# ATA5702M322 device description
Architecture: AVR8; Family: megaAVR
Registers are 8-bit, access not given, no defined reset value unless marked. A register's access mark holds for its fields unless they carry their own. Offsets are from the block's base; [hi:lo] are bit positions; {n}, {i} and the like mark numbered series.

## TPLF_CAL
Instances: TPLF_CAL 0x00
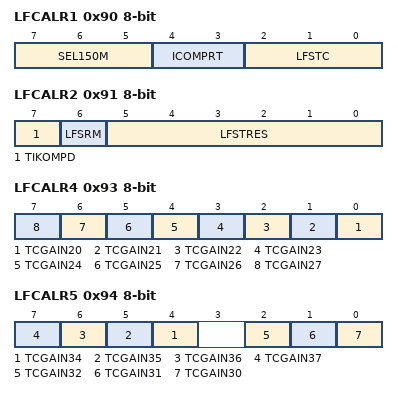
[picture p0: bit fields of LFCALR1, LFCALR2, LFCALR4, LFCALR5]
0x90 LFCALR1 — LF Receiver Calibration Register 1
  [7:5] SEL150M — Bandgap Calibration of VREF1
  [4:3] ICOMPRT — icomp_range_trim
  [2:0] LFSTC — lf_stim_trim_current
0x91 LFCALR2 — LF Receiver Calibration Register 2
  [7] TIKOMPD — trim_ikomp_data
  [6] LFSRM — lf_stim_res_mode
  [5:0] LFSTRES — lf_stim_trim_res
0x92 LFCALR3 — LF Receiver Calibration Register 3
  [7:0] TCGAIN1 — Trim coarse gain
0x93 LFCALR4 — LF Receiver Calibration Register 4
  [n-20] TCGAIN{n} (n=20..27) — Trim coarse gain bit {n-12}
0x94 LFCALR5 — LF Receiver Calibration Register 5
  [n-30] TCGAIN{n} (n=34..37) — Trim coarse gain bit {n-14}
  [2] TCGAIN32 — Trim coarse gain bit 18
  [1] TCGAIN31 — Trim coarse gain bit 17
  [0] TCGAIN30 — Trim coarse gain bit 16
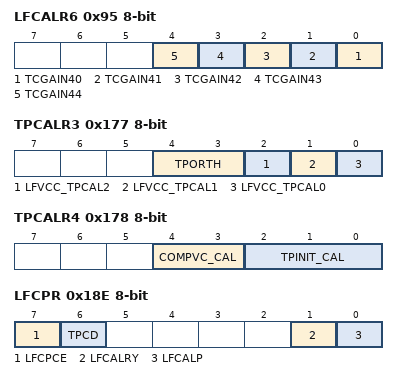
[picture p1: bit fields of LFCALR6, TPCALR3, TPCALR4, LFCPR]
0x95 LFCALR6 — LF Receiver Calibration Register 6
  [n-40] TCGAIN{n} (n=40..44) — Trim coarse gain bit {n-16}
0x96 LFCALR7 — LF Receiver Calibration Register 7
0x97 LFCALR8 bits used 4:0 — LF Receiver Calibration Register 8
0x98 LFCALR9 — LF Receiver Calibration Register 9
0x99 LFCALR10 bits used 6:0 — LF Receiver Calibration Register 10
{0x8F+i} LFCALR{i} (i=11..13) — LF Receiver Calibration Register {i}
0x9D LFCALR14 bits used 6:0 — LF Receiver Calibration Register 14
0x9E LFCALR15 — LF Receiver Calibration Register 15
0x9F LFCALR16 bits used 4:0 — LF Receiver Calibration Register 16
0xA0 LFCALR17 bits used 4:0 — LF Receiver Calibration Register 17
0xA1 LFCALR18 — LF Receiver Calibration Register 18
0xA2 LFCALR19 bits used 6:0 — LF Receiver Calibration Register 19
{0x8F+i} LFCALR{i} (i=20..22) — LF Receiver Calibration Register {i}
0xA6 LFCALR23 bits used 6:0 — LF Receiver Calibration Register 23
0xA7 LFCALR24 — LF Receiver Calibration Register 24
0xA8 LFCALR25 bits used 4:0 — LF Receiver Calibration Register 25
0xA9 LFCALR26 bits used 4:0 — LF Receiver Calibration Register 26
0xAA LFCALR27 — LF Receiver Calibration Register 27
0xAB LFCALR28 bits used 6:0 — LF Receiver Calibration Register 28
{0x8F+i} LFCALR{i} (i=29..31) — LF Receiver Calibration Register {i}
0xAF LFCALR32 bits used 6:0 — LF Receiver Calibration Register 32
0xB0 LFCALR33 — LF Receiver Calibration Register 33
0xB1 LFCALR34 bits used 4:0 — LF Receiver Calibration Register 34
0xB2 LFCALR35 — LF Receiver Calibration Register 35
0xB3 LFCALR36 bits used 6:0 — LF Receiver Calibration Register 36
0xB4 LFCALR37 bits used 5:0 — LF Receiver Calibration Register 37
{0x8F+i} LFCALR{i} bits used 3:0 (i=38..40) — LF Receiver Calibration Register {i}
{0x8F+i} LFCALR{i} (i=41..43) — LF Receiver Calibration Register {i}
0xBB LFCALR44 bits used 5:0 — LF Receiver Calibration Register 44
{0x8F+i} LFCALR{i} (i=45..47) — LF Receiver Calibration Register {i}
0xBF LFCALR48 bits used 5:0 — LF Receiver Calibration Register 48
{0x8F+i} LFCALR{i} (i=49..51) — LF Receiver Calibration Register {i}
0xC3 LFCALR52 bits used 5:0 — LF Receiver Calibration Register 52
0xC4 LFCALR53 — LF Receiver Calibration Register 53
0x175 TPCALR1 — Transponder Calibration Register 1
  [5:0] TPBG_IREF — Transponder Bandgap IREF
0x176 TPCALR2 — Transponder Calibration Register 2
  [6:0] TPBG_UREF — Transponder Bandgap UREF
0x177 TPCALR3 — Transponder Calibration Register 3
  [4:3] TPORTH — Transponder Power On Reset Threshold
  [2] LFVCC_TPCAL2 — Not used
  [1] LFVCC_TPCAL1 — Not used
  [0] LFVCC_TPCAL0 — Not used
0x178 TPCALR4 — Transponder Calibration Register 4
  [4:3] COMPVC_CAL — Comparator VC Calibration
  [2:0] TPINIT_CAL — Transponder Init Calibration
0x179 TPCALR5 bits used 3:0 — Transponder Calibration Register 5
0x17A TPCALR6 bits used 4:0 — Transponder Calibration Register 6
0x17B TPCALR7 bits used 2:0 — Transponder Calibration Register 7
0x17C TPCALR8 bits used 6:0 — Transponder Calibration Register 8
0x17D TPCALR9 — Transponder Calibration Register 9
0x17E TPCALR10 bits used 6:0 — Transponder Calibration Register 10
0x18E LFCPR — LF Receiver Calibration Protect Register
  [7] LFCPCE — LF Calibration Protect Change Enable
  [6] TPCD — Transponder Constant Disable
  [1] LFCALRY — LF Calibration Ready
  [0] LFCALP — LF Calibration Protection
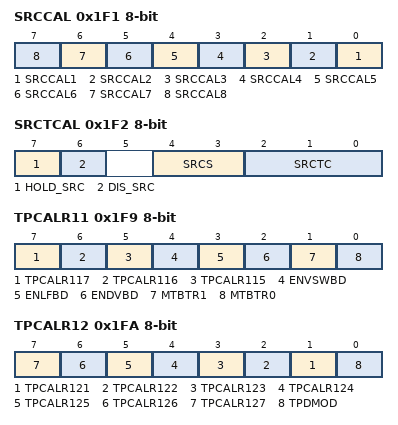
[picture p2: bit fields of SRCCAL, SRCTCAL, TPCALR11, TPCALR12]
0x1F1 SRCCAL — Slow RC oscillator calibration
  [n-1] SRCCAL{n} (n=1..8) — Slow RC oscillator calibration bit {n}
0x1F2 SRCTCAL — SRC oscillator Temperature Compensation register
  [7] HOLD_SRC — Stop SRC-Osccillator output
  [6] DIS_SRC — Disable SRC Bandgap
  [4:3] SRCS — SRC Oscillator Select delta current
  [2:0] SRCTC — SRC Oscillator Temperature Compensation
0x1F9 TPCALR11 — Transponder Calibration Register 11
  [7] TPCALR117
  [6] TPCALR116
  [5] TPCALR115
  [4] ENVSWBD — Enable VSW Brown Out Detection
  [3] ENLFBD — Enable LFVCC Brown Out Detection
  [2] ENDVBD — Enable DVCC Brown Out Detection
  [1] MTBTR1 — Measurement Buffer Trimming bit 1
  [0] MTBTR0 — Measurement Buffer Trimming bit 0
0x1FA TPCALR12 — Transponder Calibration Register 12
  [n-120] TPCALR{n} (n=121..127)
  [0] TPDMOD — Transponder Direct Modulation
0x1FB TPCALR13 — Transponder Calibration Register 13
0x1FF SRCCALL — Slow RC oscillator calibration LSB
  [0] SRCCAL0 — Slow RC oscillator calibration bit 0
